# COMPUTE_CLUSTER0_GIC500SS_GIC_ITS register map
Vendor: Texas Instruments
Peripheral module from a debugger description file (folder J721S2).
Registers are 32-bit, read-write, no defined reset value unless marked. A register's access mark holds for its fields unless they carry their own. Offsets are as the file gives them; lines under a group give offsets from that group; [hi:lo] are bit positions; {n}, {i} and the like mark numbered series; 'fields as' and 'values as' point back to an identical list; <NAME> marks a mode.

## COMPUTE_CLUSTER0_GIC500SS_GIC_ITS
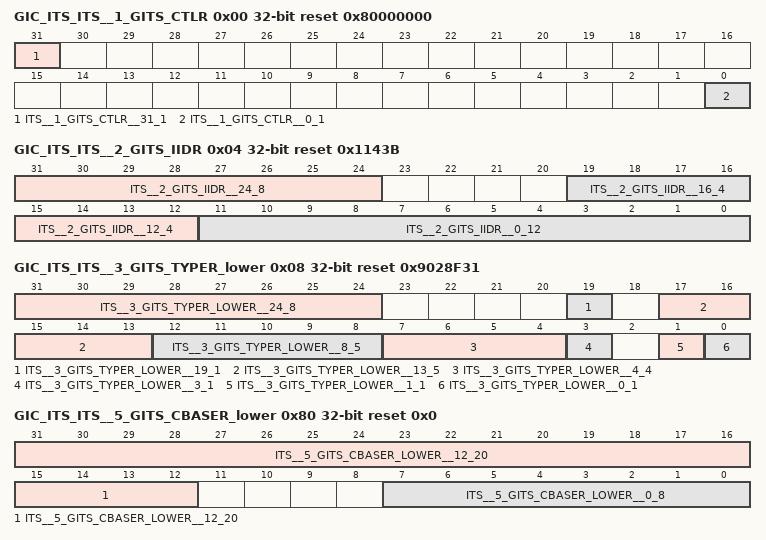
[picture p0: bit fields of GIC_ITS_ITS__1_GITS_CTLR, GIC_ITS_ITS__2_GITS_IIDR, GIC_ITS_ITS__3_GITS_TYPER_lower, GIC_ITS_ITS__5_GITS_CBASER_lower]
0x00 GIC_ITS_ITS__1_GITS_CTLR reset 0x80000000 — ITS Control Register
  [31] ITS__1_GITS_CTLR__31_1, [0] ITS__1_GITS_CTLR__0_1
0x04 GIC_ITS_ITS__2_GITS_IIDR reset 0x1143B — ITS Implementer Identification Register
  [31:24] ITS__2_GITS_IIDR__24_8, [19:16] ITS__2_GITS_IIDR__16_4, [15:12] ITS__2_GITS_IIDR__12_4, [11:0] ITS__2_GITS_IIDR__0_12
0x08 GIC_ITS_ITS__3_GITS_TYPER_lower reset 0x9028F31 — ITS Type Register (lower)
  [31:24] ITS__3_GITS_TYPER_LOWER__24_8, [19] ITS__3_GITS_TYPER_LOWER__19_1, [17:13] ITS__3_GITS_TYPER_LOWER__13_5, [12:8] ITS__3_GITS_TYPER_LOWER__8_5, [7:4] ITS__3_GITS_TYPER_LOWER__4_4, [3] ITS__3_GITS_TYPER_LOWER__3_1, [1] ITS__3_GITS_TYPER_LOWER__1_1, [0] ITS__3_GITS_TYPER_LOWER__0_1
0x0C GIC_ITS_ITS__4_GITS_TYPER_upper access not given — ITS Type Register (upper)
0x80 GIC_ITS_ITS__5_GITS_CBASER_lower reset 0x0 — Command Queue Control Register (lower)
  [31:12] ITS__5_GITS_CBASER_LOWER__12_20, [7:0] ITS__5_GITS_CBASER_LOWER__0_8
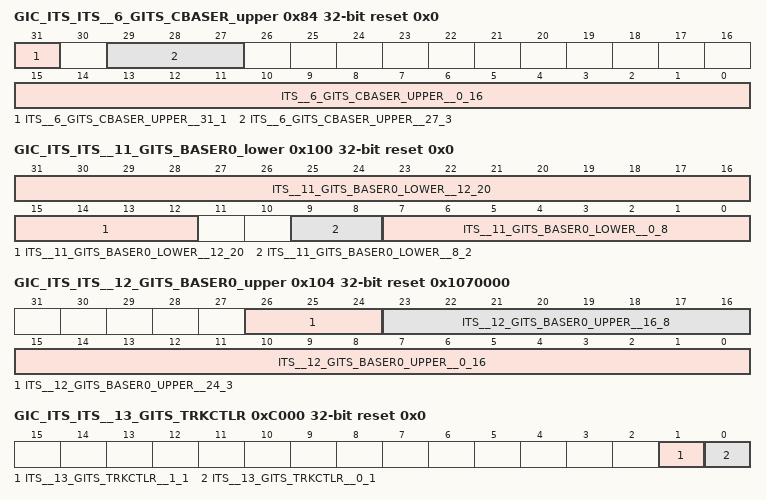
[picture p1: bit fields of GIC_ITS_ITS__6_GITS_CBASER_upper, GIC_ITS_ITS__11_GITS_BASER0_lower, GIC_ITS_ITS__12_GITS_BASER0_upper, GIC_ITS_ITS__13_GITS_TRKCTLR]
0x84 GIC_ITS_ITS__6_GITS_CBASER_upper reset 0x0 — Command Queue Control Register (upper)
  [31] ITS__6_GITS_CBASER_UPPER__31_1, [29:27] ITS__6_GITS_CBASER_UPPER__27_3, [15:0] ITS__6_GITS_CBASER_UPPER__0_16
0x88 GIC_ITS_ITS__7_GITS_CWRITER_lower reset 0x0 — Command Queue Write Pointer (lower)
  [19:5] ITS__7_GITS_CWRITER_LOWER__5_15
0x8C GIC_ITS_ITS__8_GITS_CWRITER_upper access not given — Command Queue Write Pointer (upper)
0x90 GIC_ITS_ITS__9_GITS_CREADR_lower reset 0x0 — Command Queue Read Pointer (lower)
  [19:5] ITS__9_GITS_CREADR_LOWER__5_15
0x94 GIC_ITS_ITS__10_GITS_CREADR_upper access not given — Command Queue Read Pointer (upper)
0x100 GIC_ITS_ITS__11_GITS_BASER0_lower reset 0x0 — ITS Table Control Register (lower)
  [31:12] ITS__11_GITS_BASER0_LOWER__12_20, [9:8] ITS__11_GITS_BASER0_LOWER__8_2, [7:0] ITS__11_GITS_BASER0_LOWER__0_8
0x104 GIC_ITS_ITS__12_GITS_BASER0_upper reset 0x1070000 — ITS Table Control Register (upper)
  [26:24] ITS__12_GITS_BASER0_UPPER__24_3, [23:16] ITS__12_GITS_BASER0_UPPER__16_8, [15:0] ITS__12_GITS_BASER0_UPPER__0_16
0xC000 GIC_ITS_ITS__13_GITS_TRKCTLR reset 0x0 — GIC-500 ITS Tracking Control Register
  [1] ITS__13_GITS_TRKCTLR__1_1, [0] ITS__13_GITS_TRKCTLR__0_1
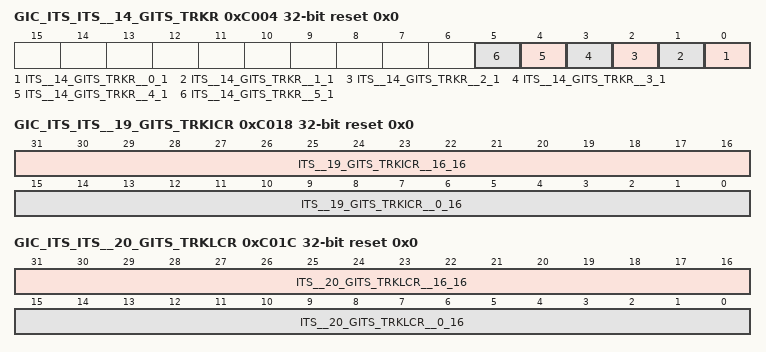
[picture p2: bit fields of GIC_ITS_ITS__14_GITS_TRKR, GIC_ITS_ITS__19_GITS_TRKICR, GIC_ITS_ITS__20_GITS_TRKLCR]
0xC004 GIC_ITS_ITS__14_GITS_TRKR reset 0x0 — GIC-500 ITS Tracking Status Register
  [n] ITS__14_GITS_TRKR__{n}_1 (n=0..5)
0xC008 GIC_ITS_ITS__15_GITS_TRKDIDR reset 0x0 — GIC-500 ITS Tracked DID Register
  [19:0] ITS__15_GITS_TRKDIDR__0_20
0xC00C GIC_ITS_ITS__16_GITS_TRKPIDR reset 0x0 — GIC-500 ITS Tracked PID Register
  [15:0] ITS__16_GITS_TRKPIDR__0_16
0xC010 GIC_ITS_ITS__17_GITS_TRKVIDR reset 0x0 — GIC-500 ITS Tracked ID Register
  [15:0] ITS__17_GITS_TRKVIDR__0_16
0xC014 GIC_ITS_ITS__18_GITS_TRKTGTR reset 0x0 — GIC-500 ITS Tracked TGT Register
  [6:0] ITS__18_GITS_TRKTGTR__0_7
0xC018 GIC_ITS_ITS__19_GITS_TRKICR reset 0x0 — GIC-500 ITE Cache Statistics Register
  [31:16] ITS__19_GITS_TRKICR__16_16, [15:0] ITS__19_GITS_TRKICR__0_16
0xC01C GIC_ITS_ITS__20_GITS_TRKLCR reset 0x0 — GIC-500 LPI Cache Statistics Register
  [31:16] ITS__20_GITS_TRKLCR__16_16, [15:0] ITS__20_GITS_TRKLCR__0_16
{0xFF7C+4i} GIC_ITS_ITS__{i}_GITS_PIDR{i-17} access not given (i=21..24) — Peripheral ID{i-17} Register
{0xFF7C+4i} GIC_ITS_ITS__{i}_GITS_PIDR{i-25} access not given (i=25..28) — Peripheral ID{i-25} Register
{0xFF7C+4i} GIC_ITS_ITS__{i}_GITS_CIDR{i-29} access not given (i=29..32) — Component ID{i-29} Register
